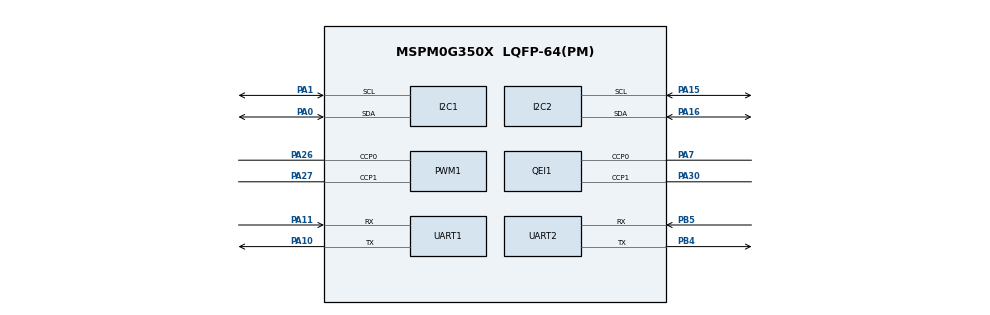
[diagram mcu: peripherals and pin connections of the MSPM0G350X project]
/**
 * @cliArgs --device "MSPM0G350X" --part "Default" --package "LQFP-64(PM)" --product "mspm0_sdk@2.10.00.04"
 * @versions {"tool":"1.27.0+4565"}
 */

/**
 * Import the modules used in this configuration.
 */
const GPIO   = scripting.addModule("/ti/driverlib/GPIO", {}, false);
const GPIO1  = GPIO.addInstance();
const GPIO2  = GPIO.addInstance();
const I2C    = scripting.addModule("/ti/driverlib/I2C", {}, false);
const I2C1   = I2C.addInstance();
const I2C2   = I2C.addInstance();
const PWM    = scripting.addModule("/ti/driverlib/PWM", {}, false);
const PWM1   = PWM.addInstance();
const QEI    = scripting.addModule("/ti/driverlib/QEI", {}, false);
const QEI1   = QEI.addInstance();
const SYSCTL = scripting.addModule("/ti/driverlib/SYSCTL");
const TIMER  = scripting.addModule("/ti/driverlib/TIMER", {}, false);
const TIMER1 = TIMER.addInstance();
const UART   = scripting.addModule("/ti/driverlib/UART", {}, false);
const UART1  = UART.addInstance();
const UART2  = UART.addInstance();

/**
 * Write custom configuration values to the imported modules.
 */
const divider2       = system.clockTree["HFCLK4MFPCLKDIV"];
divider2.divideValue = 10;

const divider5       = system.clockTree["PLL_CLK1_DIV"];
divider5.divideValue = 4;

const divider6       = system.clockTree["PLL_CLK2X_DIV"];
divider6.divideValue = 4;

const divider9       = system.clockTree["UDIV"];
divider9.divideValue = 2;

const gate7  = system.clockTree["MFCLKGATE"];
gate7.enable = true;

const gate8  = system.clockTree["MFPCLKGATE"];
gate8.enable = true;

const multiplier2         = system.clockTree["PLL_QDIV"];
multiplier2.multiplyValue = 4;

const mux4       = system.clockTree["EXHFMUX"];
mux4.inputSelect = "EXHFMUX_XTAL";

const mux8       = system.clockTree["HSCLKMUX"];
mux8.inputSelect = "HSCLKMUX_SYSPLL0";

const mux10       = system.clockTree["MFPCLKMUX"];
mux10.inputSelect = "MFPCLKMUX_HFCLK";

const mux12       = system.clockTree["SYSPLLMUX"];
mux12.inputSelect = "zSYSPLLMUX_HFCLK";

const pinFunction4        = system.clockTree["HFXT"];
pinFunction4.enable       = true;
pinFunction4.inputFreq    = 40;
pinFunction4.HFCLKMonitor = true;
pinFunction4.HFXTStartup  = 10;

GPIO1.$name                              = "DEBUG_LED";
GPIO1.associatedPins[0].$name            = "PIN_22";
GPIO1.associatedPins[0].assignedPort     = "PORTB";
GPIO1.associatedPins[0].assignedPin      = "22";
GPIO1.associatedPins[0].internalResistor = "PULL_DOWN";

const Board = scripting.addModule("/ti/driverlib/Board", {}, false);

GPIO2.$name                              = "GPIO_KEY";
GPIO2.associatedPins.create(4);
GPIO2.associatedPins[0].$name            = "PIN_UP";
GPIO2.associatedPins[0].direction        = "INPUT";
GPIO2.associatedPins[0].internalResistor = "PULL_UP";
GPIO2.associatedPins[0].assignedPort     = "PORTA";
GPIO2.associatedPins[0].assignedPin      = "9";
GPIO2.associatedPins[1].$name            = "PIN_LEFT";
GPIO2.associatedPins[1].direction        = "INPUT";
GPIO2.associatedPins[1].internalResistor = "PULL_UP";
GPIO2.associatedPins[1].assignedPort     = "PORTA";
GPIO2.associatedPins[1].assignedPin      = "8";
GPIO2.associatedPins[2].$name            = "PIN_RIGHT";
GPIO2.associatedPins[2].direction        = "INPUT";
GPIO2.associatedPins[2].internalResistor = "PULL_UP";
GPIO2.associatedPins[2].assignedPort     = "PORTA";
GPIO2.associatedPins[2].assignedPin      = "31";
GPIO2.associatedPins[3].$name            = "PIN_DOWN";
GPIO2.associatedPins[3].direction        = "INPUT";
GPIO2.associatedPins[3].internalResistor = "PULL_UP";
GPIO2.associatedPins[3].assignedPort     = "PORTA";
GPIO2.associatedPins[3].assignedPin      = "28";

I2C1.$name                             = "I2C0";
I2C1.basicEnableController             = true;
I2C1.interruptPriority                 = "3";
I2C1.basicControllerStandardBusSpeed   = "Fast";
I2C1.advControllerRXFIFOTRIG           = "BYTES_2";
I2C1.intController                     = ["NACK","RXFIFO_FULL","RX_DONE","START","STOP","TXFIFO_EMPTY","TX_DONE"];
I2C1.peripheral.$assign                = "I2C0";
I2C1.peripheral.sdaPin.$assign         = "PA0";
I2C1.peripheral.sclPin.$assign         = "PA1";
I2C1.sdaPinConfig.hideOutputInversion  = scripting.forceWrite(false);
I2C1.sdaPinConfig.onlyInternalResistor = scripting.forceWrite(false);
I2C1.sdaPinConfig.passedPeripheralType = scripting.forceWrite("Digital");
I2C1.sdaPinConfig.$name                = "ti_driverlib_gpio_GPIOPinGeneric2";
I2C1.sclPinConfig.hideOutputInversion  = scripting.forceWrite(false);
I2C1.sclPinConfig.onlyInternalResistor = scripting.forceWrite(false);
I2C1.sclPinConfig.passedPeripheralType = scripting.forceWrite("Digital");
I2C1.sclPinConfig.$name                = "ti_driverlib_gpio_GPIOPinGeneric3";

I2C2.$name                             = "I2C1";
I2C2.basicEnableController             = true;
I2C2.basicControllerStandardBusSpeed   = "Fast";
I2C2.advControllerRXFIFOTRIG           = "BYTES_8";
I2C2.intController                     = ["NACK","RXFIFO_FULL","RX_DONE","START","STOP","TXFIFO_EMPTY","TX_DONE"];
I2C2.peripheral.$assign                = "I2C1";
I2C2.peripheral.sdaPin.$assign         = "PA16";
I2C2.peripheral.sclPin.$assign         = "PA15";
I2C2.sdaPinConfig.$name                = "ti_driverlib_gpio_GPIOPinGeneric10";
I2C2.sdaPinConfig.hideOutputInversion  = scripting.forceWrite(false);
I2C2.sdaPinConfig.onlyInternalResistor = scripting.forceWrite(false);
I2C2.sdaPinConfig.passedPeripheralType = scripting.forceWrite("Digital");
I2C2.sclPinConfig.$name                = "ti_driverlib_gpio_GPIOPinGeneric11";
I2C2.sclPinConfig.hideOutputInversion  = scripting.forceWrite(false);
I2C2.sclPinConfig.onlyInternalResistor = scripting.forceWrite(false);
I2C2.sclPinConfig.passedPeripheralType = scripting.forceWrite("Digital");

PWM1.$name                              = "PWM_MOTOR";
PWM1.timerStartTimer                    = true;
PWM1.timerCount                         = 10000;
PWM1.peripheral.$assign                 = "TIMG7";
PWM1.peripheral.ccp0Pin.$assign         = "PA26";
PWM1.peripheral.ccp1Pin.$assign         = "PA27";
PWM1.PWM_CHANNEL_0.$name                = "ti_driverlib_pwm_PWMTimerCC0";
PWM1.PWM_CHANNEL_1.$name                = "ti_driverlib_pwm_PWMTimerCC1";
PWM1.ccp0PinConfig.direction            = scripting.forceWrite("OUTPUT");
PWM1.ccp0PinConfig.hideOutputInversion  = scripting.forceWrite(false);
PWM1.ccp0PinConfig.onlyInternalResistor = scripting.forceWrite(false);
PWM1.ccp0PinConfig.passedPeripheralType = scripting.forceWrite("Digital");
PWM1.ccp0PinConfig.$name                = "ti_driverlib_gpio_GPIOPinGeneric4";
PWM1.ccp1PinConfig.direction            = scripting.forceWrite("OUTPUT");
PWM1.ccp1PinConfig.hideOutputInversion  = scripting.forceWrite(false);
PWM1.ccp1PinConfig.onlyInternalResistor = scripting.forceWrite(false);
PWM1.ccp1PinConfig.passedPeripheralType = scripting.forceWrite("Digital");
PWM1.ccp1PinConfig.$name                = "ti_driverlib_gpio_GPIOPinGeneric5";

QEI1.$name                      = "QEI_0";
QEI1.timerStartTimer            = true;
QEI1.peripheral.$assign         = "TIMG8";
QEI1.peripheral.ccp0Pin.$assign = "PA7";
QEI1.peripheral.ccp1Pin.$assign = "PA30";
QEI1.ccp0PinConfig.$name        = "ti_driverlib_gpio_GPIOPinGeneric8";
QEI1.ccp1PinConfig.$name        = "ti_driverlib_gpio_GPIOPinGeneric9";

SYSCTL.forceDefaultClkConfig = true;
SYSCTL.clockTreeEn           = true;

TIMER1.$name             = "TIMER_TICK";
TIMER1.timerClkDiv       = 8;
TIMER1.timerClkPrescale  = 10;
TIMER1.timerMode         = "PERIODIC";
TIMER1.timerPeriod       = "20 ms";
TIMER1.timerStartTimer   = true;
TIMER1.interrupts        = ["ZERO"];
TIMER1.interruptPriority = "3";

UART1.interruptPriority                 = "3";
UART1.targetBaudRate                    = 115200;
UART1.enabledDMATXTriggers              = "DL_UART_DMA_INTERRUPT_TX";
UART1.$name                             = "UART0";
UART1.rxTimeoutValue                    = 4;
UART1.enableFIFO                        = true;
UART1.enabledInterrupts                 = ["DMA_DONE_TX","RX","RX_TIMEOUT_ERROR"];
UART1.enableDMARX                       = false;
UART1.txFifoThreshold                   = "DL_UART_TX_FIFO_LEVEL_EMPTY";
UART1.rxFifoThreshold                   = "DL_UART_RX_FIFO_LEVEL_FULL";
UART1.peripheral.$assign                = "UART0";
UART1.peripheral.rxPin.$assign          = "PA11";
UART1.peripheral.txPin.$assign          = "PA10";
UART1.txPinConfig.direction             = scripting.forceWrite("OUTPUT");
UART1.txPinConfig.hideOutputInversion   = scripting.forceWrite(false);
UART1.txPinConfig.onlyInternalResistor  = scripting.forceWrite(false);
UART1.txPinConfig.passedPeripheralType  = scripting.forceWrite("Digital");
UART1.txPinConfig.$name                 = "ti_driverlib_gpio_GPIOPinGeneric0";
UART1.rxPinConfig.hideOutputInversion   = scripting.forceWrite(false);
UART1.rxPinConfig.onlyInternalResistor  = scripting.forceWrite(false);
UART1.rxPinConfig.passedPeripheralType  = scripting.forceWrite("Digital");
UART1.rxPinConfig.$name                 = "ti_driverlib_gpio_GPIOPinGeneric1";
UART1.DMA_CHANNEL_TX.$name              = "DMA_CH0";
UART1.DMA_CHANNEL_TX.addressMode        = "b2f";
UART1.DMA_CHANNEL_TX.dstLength          = "BYTE";
UART1.DMA_CHANNEL_TX.srcLength          = "BYTE";
UART1.DMA_CHANNEL_TX.peripheral.$assign = "DMA_CH0";

UART2.$name                             = "UART1";
UART2.targetBaudRate                    = 115200;
UART2.enableFIFO                        = true;
UART2.rxFifoThreshold                   = "DL_UART_RX_FIFO_LEVEL_FULL";
UART2.txFifoThreshold                   = "DL_UART_TX_FIFO_LEVEL_EMPTY";
UART2.enabledInterrupts                 = ["DMA_DONE_TX","RX","RX_TIMEOUT_ERROR"];
UART2.interruptPriority                 = "3";
UART2.enabledDMATXTriggers              = "DL_UART_DMA_INTERRUPT_TX";
UART2.peripheral.$assign                = "UART1";
UART2.peripheral.rxPin.$assign          = "PB5";
UART2.peripheral.txPin.$assign          = "PB4";
UART2.txPinConfig.direction             = scripting.forceWrite("OUTPUT");
UART2.txPinConfig.hideOutputInversion   = scripting.forceWrite(false);
UART2.txPinConfig.onlyInternalResistor  = scripting.forceWrite(false);
UART2.txPinConfig.passedPeripheralType  = scripting.forceWrite("Digital");
UART2.txPinConfig.$name                 = "ti_driverlib_gpio_GPIOPinGeneric6";
UART2.rxPinConfig.hideOutputInversion   = scripting.forceWrite(false);
UART2.rxPinConfig.onlyInternalResistor  = scripting.forceWrite(false);
UART2.rxPinConfig.passedPeripheralType  = scripting.forceWrite("Digital");
UART2.rxPinConfig.$name                 = "ti_driverlib_gpio_GPIOPinGeneric7";
UART2.DMA_CHANNEL_TX.$name              = "DMA_CH1";
UART2.DMA_CHANNEL_TX.srcLength          = "BYTE";
UART2.DMA_CHANNEL_TX.dstLength          = "BYTE";
UART2.DMA_CHANNEL_TX.addressMode        = "b2f";
UART2.DMA_CHANNEL_TX.peripheral.$assign = "DMA_CH1";

/**
 * Pinmux solution for unlocked pins/peripherals. This ensures that minor changes to the automatic solver in a future
 * version of the tool will not impact the pinmux you originally saw.  These lines can be completely deleted in order to
 * re-solve from scratch.
 */
pinFunction4.peripheral.$suggestSolution           = "SYSCTL";
pinFunction4.peripheral.hfxInPin.$suggestSolution  = "PA5";
pinFunction4.peripheral.hfxOutPin.$suggestSolution = "PA6";
GPIO1.associatedPins[0].pin.$suggestSolution       = "PB22";
Board.peripheral.$suggestSolution                  = "DEBUGSS";
Board.peripheral.swclkPin.$suggestSolution         = "PA20";
Board.peripheral.swdioPin.$suggestSolution         = "PA19";
GPIO2.associatedPins[0].pin.$suggestSolution       = "PA9";
GPIO2.associatedPins[1].pin.$suggestSolution       = "PA8";
GPIO2.associatedPins[2].pin.$suggestSolution       = "PA31";
GPIO2.associatedPins[3].pin.$suggestSolution       = "PA28";
TIMER1.peripheral.$suggestSolution                 = "TIMA0";
